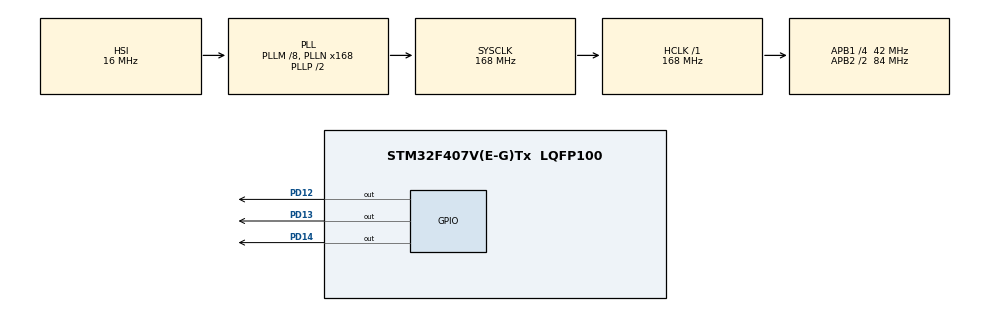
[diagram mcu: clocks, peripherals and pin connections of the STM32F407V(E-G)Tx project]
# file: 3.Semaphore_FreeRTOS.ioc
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Mcu.Family=STM32F4
Mcu.Name=STM32F407V(E-G)Tx
Mcu.Package=LQFP100
NVIC.PriorityGroup=NVIC_PRIORITYGROUP_4
NVIC.TIM5_IRQn=true\:0\:0\:false\:false\:true\:false\:true\:true
NVIC.TimeBase=TIM5_IRQn
NVIC.TimeBaseIP=TIM5
PA13.Mode=Serial_Wire
PA13.Signal=SYS_JTMS-SWDIO
PA14.Mode=Serial_Wire
PA14.Signal=SYS_JTCK-SWCLK
PD12.Signal=GPIO_Output
PD13.Signal=GPIO_Output
PD14.Signal=GPIO_Output
ProjectManager.HeapSize=0x200
ProjectManager.StackSize=0x400
ProjectManager.TargetToolchain=STM32CubeIDE
RCC.48MHZClocksFreq_Value=48000000
RCC.AHBFreq_Value=168000000
RCC.APB1CLKDivider=RCC_HCLK_DIV4
RCC.APB1Freq_Value=42000000
RCC.APB1TimFreq_Value=84000000
RCC.APB2CLKDivider=RCC_HCLK_DIV2
RCC.APB2Freq_Value=84000000
RCC.APB2TimFreq_Value=168000000
RCC.CortexFreq_Value=168000000
RCC.HCLKFreq_Value=168000000
RCC.HSE_VALUE=8000000
RCC.HSI_VALUE=16000000
RCC.LSE_VALUE=32768
RCC.PLLM=8
RCC.PLLN=168
RCC.PLLQ=7
RCC.SYSCLKFreq_VALUE=168000000
RCC.SYSCLKSource=RCC_SYSCLKSOURCE_PLLCLK
RCC.VCOOutputFreq_Value=336000000
VP_SYS_VS_tim5.Mode=TIM5
board=STM32F407G-DISC1

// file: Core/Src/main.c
/* USER CODE BEGIN Header */
/**
  ******************************************************************************
  * @file           : main.c
  * @brief          : Main program body
  ******************************************************************************
  * @attention
  *
  * Copyright (c) 2024 STMicroelectronics.
  * All rights reserved.
  *
  * This software is licensed under terms that can be found in the LICENSE file
  * in the root directory of this software component.
  * If no LICENSE file comes with this software, it is provided AS-IS.
  *
  ******************************************************************************
  */
/* USER CODE END Header */
#include "main.h"

/* USER CODE BEGIN Includes */

#include "FreeRTOS.h"
#include "task.h"
#include "queue.h"
#include "semphr.h"

/* USER CODE END Includes */

/* USER CODE BEGIN PD */

#define LED_PORT		GPIOD
#define GREEN_LED 		GPIO_PIN_12
#define ORANGE_LED 		GPIO_PIN_13
#define RED_LED 		GPIO_PIN_14

/* USER CODE END PD */

/* USER CODE BEGIN PV */

uint32_t greenTaskProfiler;
uint32_t orangeTaskProfiler;
uint32_t redTaskProfiler;

SemaphoreHandle_t xBinarySemaphore;

/* USER CODE END PV */

void SystemClock_Config(void);
static void MX_GPIO_Init(void);

/* USER CODE BEGIN 0 */

void GreenLedTask(void *pvParameters) {
	xSemaphoreGive(xBinarySemaphore);
	while (1) {
		xSemaphoreTake(xBinarySemaphore, portMAX_DELAY);
		HAL_GPIO_TogglePin(LED_PORT, GREEN_LED);
		greenTaskProfiler++;
		xSemaphoreGive(xBinarySemaphore);
	}
}

void OrangeLedTask(void *pvParameters) {
	while (1) {
		xSemaphoreTake(xBinarySemaphore, portMAX_DELAY);
		HAL_GPIO_TogglePin(LED_PORT, ORANGE_LED);
		orangeTaskProfiler++;
		xSemaphoreGive(xBinarySemaphore);

	}
}

void redLedTask(void *pvParameters) {
	while (1) {
		xSemaphoreTake(xBinarySemaphore, portMAX_DELAY);
		HAL_GPIO_TogglePin(LED_PORT, RED_LED);
		redTaskProfiler++;
		xSemaphoreGive(xBinarySemaphore);

	}
}
/* USER CODE END 0 */

int main(void)
{

  /* MCU Configuration--------------------------------------------------------*/

  /* Reset of all peripherals, Initializes the Flash interface and the Systick. */
  HAL_Init();

  /* Configure the system clock */
  SystemClock_Config();

  /* Initialize all configured peripherals */
  MX_GPIO_Init();
  /* USER CODE BEGIN 2 */

  	xBinarySemaphore = xSemaphoreCreateBinary();
  	xTaskCreate(GreenLedTask, "LED green task", 200, NULL, 2, NULL);
	  xTaskCreate(OrangeLedTask, "LED orange task", 200, NULL, 2, NULL);
	  xTaskCreate(redLedTask,"LED red task", 200, NULL, 2, NULL);

	vTaskStartScheduler();

  /* USER CODE END 2 */

  /* Infinite loop */
  while (1)
  {

  }
}

void SystemClock_Config(void)
{
  RCC_OscInitTypeDef RCC_OscInitStruct = {0};
  RCC_ClkInitTypeDef RCC_ClkInitStruct = {0};

  /** Configure the main internal regulator output voltage
  */
  __HAL_RCC_PWR_CLK_ENABLE();
  __HAL_PWR_VOLTAGESCALING_CONFIG(PWR_REGULATOR_VOLTAGE_SCALE1);

  /** Initializes the RCC Oscillators according to the specified parameters
  * in the RCC_OscInitTypeDef structure.
  */
  RCC_OscInitStruct.OscillatorType = RCC_OSCILLATORTYPE_HSI;
  RCC_OscInitStruct.HSIState = RCC_HSI_ON;
  RCC_OscInitStruct.HSICalibrationValue = RCC_HSICALIBRATION_DEFAULT;
  RCC_OscInitStruct.PLL.PLLState = RCC_PLL_ON;
  RCC_OscInitStruct.PLL.PLLSource = RCC_PLLSOURCE_HSI;
  RCC_OscInitStruct.PLL.PLLM = 8;
  RCC_OscInitStruct.PLL.PLLN = 168;
  RCC_OscInitStruct.PLL.PLLP = RCC_PLLP_DIV2;
  RCC_OscInitStruct.PLL.PLLQ = 7;
  if (HAL_RCC_OscConfig(&RCC_OscInitStruct) != HAL_OK)
  {
    Error_Handler();
  }

  /** Initializes the CPU, AHB and APB buses clocks
  */
  RCC_ClkInitStruct.ClockType = RCC_CLOCKTYPE_HCLK|RCC_CLOCKTYPE_SYSCLK
                              |RCC_CLOCKTYPE_PCLK1|RCC_CLOCKTYPE_PCLK2;
  RCC_ClkInitStruct.SYSCLKSource = RCC_SYSCLKSOURCE_PLLCLK;
  RCC_ClkInitStruct.AHBCLKDivider = RCC_SYSCLK_DIV1;
  RCC_ClkInitStruct.APB1CLKDivider = RCC_HCLK_DIV4;
  RCC_ClkInitStruct.APB2CLKDivider = RCC_HCLK_DIV2;

  if (HAL_RCC_ClockConfig(&RCC_ClkInitStruct, FLASH_LATENCY_5) != HAL_OK)
  {
    Error_Handler();
  }
}

static void MX_GPIO_Init(void)
{
  GPIO_InitTypeDef GPIO_InitStruct = {0};

  /* GPIO Ports Clock Enable */
  __HAL_RCC_GPIOD_CLK_ENABLE();
  __HAL_RCC_GPIOA_CLK_ENABLE();

  /*Configure GPIO pin Output Level */
  HAL_GPIO_WritePin(GPIOD, GPIO_PIN_12|GPIO_PIN_13|GPIO_PIN_14, GPIO_PIN_RESET);

  /*Configure GPIO pins : PD12 PD13 PD14 */
  GPIO_InitStruct.Pin = GPIO_PIN_12|GPIO_PIN_13|GPIO_PIN_14;
  GPIO_InitStruct.Mode = GPIO_MODE_OUTPUT_PP;
  GPIO_InitStruct.Pull = GPIO_NOPULL;
  GPIO_InitStruct.Speed = GPIO_SPEED_FREQ_LOW;
  HAL_GPIO_Init(GPIOD, &GPIO_InitStruct);

}

void HAL_TIM_PeriodElapsedCallback(TIM_HandleTypeDef *htim)
{
  if (htim->Instance == TIM5) {
    HAL_IncTick();
  }
}

void Error_Handler(void)
{
  __disable_irq();
  while (1)
  {
  }
}
